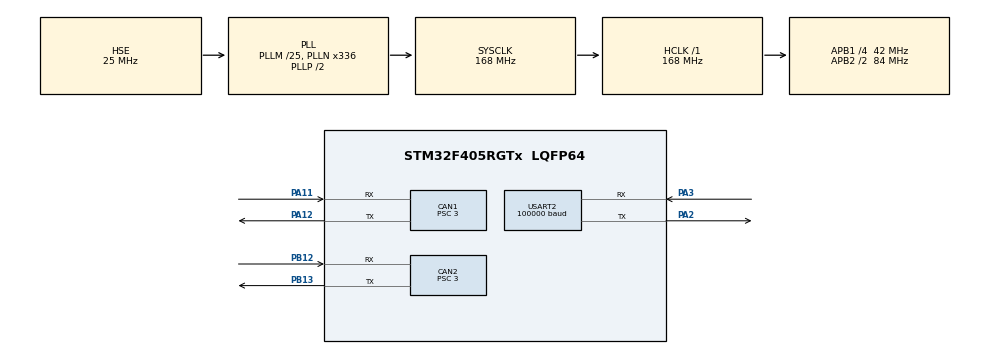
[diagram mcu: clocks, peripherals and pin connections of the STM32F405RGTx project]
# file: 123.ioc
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CAN1.BS1=CAN_BS1_9TQ
CAN1.BS2=CAN_BS2_4TQ
CAN1.CalculateTimeQuantum=71.42857142857143
CAN1.Prescaler=3
CAN2.BS1=CAN_BS1_9TQ
CAN2.BS2=CAN_BS2_4TQ
CAN2.CalculateTimeQuantum=71.42857142857143
CAN2.Prescaler=3
Dma.Request0=USART2_RX
Dma.USART2_RX.0.Direction=DMA_PERIPH_TO_MEMORY
Dma.USART2_RX.0.FIFOMode=DMA_FIFOMODE_DISABLE
Dma.USART2_RX.0.Instance=DMA1_Stream5
Dma.USART2_RX.0.MemDataAlignment=DMA_MDATAALIGN_BYTE
Dma.USART2_RX.0.MemInc=DMA_MINC_ENABLE
Dma.USART2_RX.0.Mode=DMA_NORMAL
Dma.USART2_RX.0.PeriphDataAlignment=DMA_PDATAALIGN_BYTE
Dma.USART2_RX.0.PeriphInc=DMA_PINC_DISABLE
Dma.USART2_RX.0.Priority=DMA_PRIORITY_VERY_HIGH
Mcu.Family=STM32F4
Mcu.Name=STM32F405RGTx
Mcu.Package=LQFP64
NVIC.CAN1_RX0_IRQn=true\:1\:0\:true\:false\:true\:true\:true
NVIC.CAN2_RX0_IRQn=true\:1\:0\:true\:false\:true\:true\:true
NVIC.DMA1_Stream5_IRQn=true\:0\:0\:false\:false\:false\:false\:false
NVIC.PriorityGroup=NVIC_PRIORITYGROUP_4
NVIC.USART2_IRQn=true\:0\:0\:false\:false\:false\:true\:false
PA11.Mode=Master
PA11.Signal=CAN1_RX
PA12.Mode=Master
PA12.Signal=CAN1_TX
PA13.Mode=Serial_Wire
PA13.Signal=SYS_JTMS-SWDIO
PA14.Mode=Serial_Wire
PA14.Signal=SYS_JTCK-SWCLK
PA2.Mode=Asynchronous
PA2.Signal=USART2_TX
PA3.Mode=Asynchronous
PA3.Signal=USART2_RX
PB12.Mode=Slave
PB12.Signal=CAN2_RX
PB13.Mode=Slave
PB13.Signal=CAN2_TX
PH0-OSC_IN.Mode=HSE-External-Oscillator
PH0-OSC_IN.Signal=RCC_OSC_IN
PH1-OSC_OUT.Mode=HSE-External-Oscillator
PH1-OSC_OUT.Signal=RCC_OSC_OUT
ProjectManager.HeapSize=0x200
ProjectManager.StackSize=0x400
ProjectManager.TargetToolchain=MDK-ARM V5.27
RCC.48MHZClocksFreq_Value=84000000
RCC.AHBFreq_Value=168000000
RCC.APB1CLKDivider=RCC_HCLK_DIV4
RCC.APB1Freq_Value=42000000
RCC.APB1TimFreq_Value=84000000
RCC.APB2CLKDivider=RCC_HCLK_DIV2
RCC.APB2Freq_Value=84000000
RCC.APB2TimFreq_Value=168000000
RCC.CortexFreq_Value=168000000
RCC.HCLKFreq_Value=168000000
RCC.HSE_VALUE=25000000
RCC.HSI_VALUE=16000000
RCC.LSE_VALUE=32768
RCC.PLLM=25
RCC.PLLN=336
RCC.PLLSourceVirtual=RCC_PLLSOURCE_HSE
RCC.SYSCLKFreq_VALUE=168000000
RCC.SYSCLKSource=RCC_SYSCLKSOURCE_PLLCLK
RCC.VCOOutputFreq_Value=336000000
USART2.BaudRate=100000
USART2.Mode=MODE_TX_RX
USART2.Parity=PARITY_EVEN
USART2.VirtualMode=VM_ASYNC
board=custom

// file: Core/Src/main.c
/* USER CODE BEGIN Header */
/**
  ******************************************************************************
  * @file           : main.c
  * @brief          : Main program body
  ******************************************************************************
  * @attention
  *
  * <h2><center>&copy; Copyright (c) 2020 STMicroelectronics.
  * All rights reserved.</center></h2>
  *
  * This software component is licensed by ST under BSD 3-Clause license,
  * the "License"; You may not use this file except in compliance with the
  * License. You may obtain a copy of the License at:
  *                        opensource.org/licenses/BSD-3-Clause
  *
  ******************************************************************************
  */
/* USER CODE END Header */
#include "main.h"
#include "can.h"
#include "dma.h"
#include "usart.h"
#include "gpio.h"

/* USER CODE BEGIN Includes */
#include "remote_control.h"
#include "bsp_can.h"
#include "CAN_receive.h"
#include "pid.h"
#include "chassis.h"
/* USER CODE END Includes */

/* USER CODE BEGIN PTD */
float kp=7.0,ki=0.1,kd=0.0;
/* USER CODE END PTD */

void SystemClock_Config(void);

int main(void)
{

  /* MCU Configuration--------------------------------------------------------*/

  /* Reset of all peripherals, Initializes the Flash interface and the Systick. */
  HAL_Init();

  /* Configure the system clock */
  SystemClock_Config();

  /* Initialize all configured peripherals */
  MX_GPIO_Init();
  MX_DMA_Init();
  MX_USART2_UART_Init();
  MX_CAN1_Init();
  MX_CAN2_Init();
  /* USER CODE BEGIN 2 */
remote_control_init();
can_filter_init();
  /* USER CODE END 2 */

  /* Infinite loop */
  while (1)
  {

    /* USER CODE BEGIN 3 */
		for(int i=0; i<4; i++)
			PID_struct_init(&pid_spd[i], POSITION_PID, 20000, 20000,kp,ki,kd);
		chassis_control_loop();
		HAL_Delay(2);
  }
  /* USER CODE END 3 */
}

void SystemClock_Config(void)
{
  RCC_OscInitTypeDef RCC_OscInitStruct = {0};
  RCC_ClkInitTypeDef RCC_ClkInitStruct = {0};

  /** Configure the main internal regulator output voltage
  */
  __HAL_RCC_PWR_CLK_ENABLE();
  __HAL_PWR_VOLTAGESCALING_CONFIG(PWR_REGULATOR_VOLTAGE_SCALE1);
  /** Initializes the RCC Oscillators according to the specified parameters
  * in the RCC_OscInitTypeDef structure.
  */
  RCC_OscInitStruct.OscillatorType = RCC_OSCILLATORTYPE_HSE;
  RCC_OscInitStruct.HSEState = RCC_HSE_ON;
  RCC_OscInitStruct.PLL.PLLState = RCC_PLL_ON;
  RCC_OscInitStruct.PLL.PLLSource = RCC_PLLSOURCE_HSE;
  RCC_OscInitStruct.PLL.PLLM = 25;
  RCC_OscInitStruct.PLL.PLLN = 336;
  RCC_OscInitStruct.PLL.PLLP = RCC_PLLP_DIV2;
  RCC_OscInitStruct.PLL.PLLQ = 4;
  if (HAL_RCC_OscConfig(&RCC_OscInitStruct) != HAL_OK)
  {
    Error_Handler();
  }
  /** Initializes the CPU, AHB and APB buses clocks
  */
  RCC_ClkInitStruct.ClockType = RCC_CLOCKTYPE_HCLK|RCC_CLOCKTYPE_SYSCLK
                              |RCC_CLOCKTYPE_PCLK1|RCC_CLOCKTYPE_PCLK2;
  RCC_ClkInitStruct.SYSCLKSource = RCC_SYSCLKSOURCE_PLLCLK;
  RCC_ClkInitStruct.AHBCLKDivider = RCC_SYSCLK_DIV1;
  RCC_ClkInitStruct.APB1CLKDivider = RCC_HCLK_DIV4;
  RCC_ClkInitStruct.APB2CLKDivider = RCC_HCLK_DIV2;

  if (HAL_RCC_ClockConfig(&RCC_ClkInitStruct, FLASH_LATENCY_5) != HAL_OK)
  {
    Error_Handler();
  }
}

void Error_Handler(void)
{
}

/************************ (C) COPYRIGHT STMicroelectronics *****END OF FILE****/
